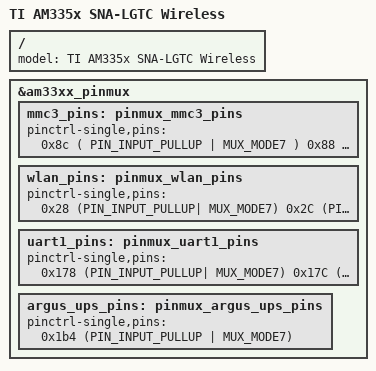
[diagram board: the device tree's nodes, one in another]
/dts-v1/;

#include "am335x-lgtc.dtsi"

/ {
	model = "TI AM335x SNA-LGTC Wireless";
};

/* set MMC3 pins as GPIOs */
&am33xx_pinmux {
	mmc3_pins: pinmux_mmc3_pins {
		pinctrl-single,pins = <
			0x8c ( PIN_INPUT_PULLUP | MUX_MODE7 ) /* gpio2_1 gpmc_clk.mmc2_clk */
			0x88 ( PIN_INPUT_PULLUP | MUX_MODE7 ) /* gpio2_0 gpmc_csn3.mmc2_cmd */
			0x30 ( PIN_INPUT_PULLUP | MUX_MODE7 ) /* gpio1_12 gpmc_ad12.mmc2_dat0 */
			0x34 ( PIN_INPUT_PULLUP | MUX_MODE7 ) /* gpio1_13 gpmc_ad13.mmc2_dat1 */
			0x38 ( PIN_INPUT_PULLUP | MUX_MODE7 ) /* gpio1_14 gpmc_ad14.mmc2_dat2 */
			0x3c ( PIN_INPUT_PULLUP | MUX_MODE7 ) /* gpio1_15 gpmc_ad15.mmc2_dat3 */
		>;
	};

	/* wl18xx card enable/irq GPIOs. */
	wlan_pins: pinmux_wlan_pins {
		pinctrl-single,pins = <
			0x28 (PIN_INPUT_PULLUP| MUX_MODE7)	/* gpmc_ad10.gpio0_26 WL_EN*/
			0x2C (PIN_INPUT_PULLUP | MUX_MODE7)	/* gpmc_ad11.gpio0_27 WL_IRQ*/
			0x7C (PIN_INPUT_PULLUP | MUX_MODE7)	/* gpmc_csn0.gpio1_29 Cape_Buffer_EN*/
		>;
	};

	uart1_pins: pinmux_uart1_pins {
		pinctrl-single,pins = <
			0x178 (PIN_INPUT_PULLUP| MUX_MODE7)		/* uart1_ctsn.uart1_ctsn */
			0x17C (PIN_INPUT_PULLUP| MUX_MODE7)	/* uart1_rtsn.uart1_rtsn */
			0x180 (PIN_INPUT_PULLUP| MUX_MODE7)	/* uart1_rxd.uart1_rxd */
			0x184 (PIN_INPUT_PULLUP| MUX_MODE7)	/* uart1_txd.uart1_txd */
		>;
	};

	argus_ups_pins: pinmux_argus_ups_pins { /* Set up pinmux */
		pinctrl-single,pins = <
			0x1b4 (PIN_INPUT_PULLUP | MUX_MODE7) /* xdma_event_intr1.gpio0_20 */
		>;
	};
};
